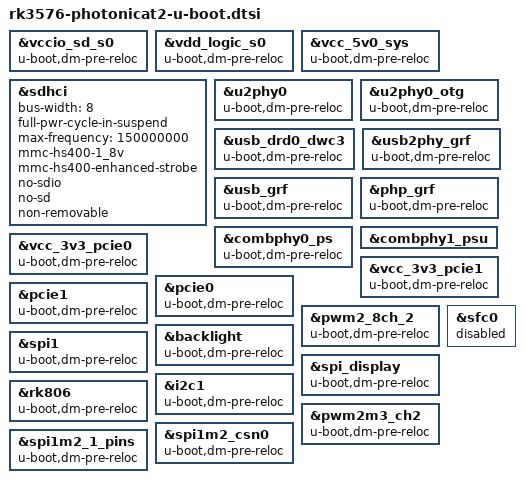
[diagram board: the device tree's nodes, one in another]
// SPDX-License-Identifier: (GPL-2.0+ OR MIT)
/*
 * Copyright (c) 2025 Rockchip Electronics Co., Ltd.
 * Copyright (c) 2025 Radxa Computer (Shenzhen) Co., Ltd.
*/

#include "rockchip/rk3576-u-boot.dtsi"

&vccio_sd_s0 {
	u-boot,dm-pre-reloc;
};

&vdd_logic_s0 {
	u-boot,dm-pre-reloc;
};

&vcc_5v0_sys {
	u-boot,dm-pre-reloc;
};

&sdhci {
	bus-width = <8>;
	full-pwr-cycle-in-suspend;
	max-frequency = <150000000>;
	mmc-hs400-1_8v;
	mmc-hs400-enhanced-strobe;

	/delete-property/ supports-cqe;

	no-sdio;
	no-sd;
	non-removable;
	status = "okay";
};

&u2phy0 {
	u-boot,dm-pre-reloc;
};

&u2phy0_otg {
	u-boot,dm-pre-reloc;
};

&usb_drd0_dwc3 {
	u-boot,dm-pre-reloc;
};

&usb2phy_grf {
	u-boot,dm-pre-reloc;
};

&usb_grf {
	u-boot,dm-pre-reloc;
};

&php_grf {
	u-boot,dm-pre-reloc;
};

&combphy0_ps {
	u-boot,dm-pre-reloc;
};

&combphy1_psu {
	status = "okay";
};

&vcc_3v3_pcie0 {
	u-boot,dm-pre-reloc;
};

&vcc_3v3_pcie1 {
	u-boot,dm-pre-reloc;
};

&pcie0 {
	u-boot,dm-pre-reloc;
};

&pcie1 {
	u-boot,dm-pre-reloc;
};

&pwm2_8ch_2 {
	u-boot,dm-pre-reloc;
};

&backlight {
	u-boot,dm-pre-reloc;
};

&spi1 {
	u-boot,dm-pre-reloc;
};

&spi_display {
	u-boot,dm-pre-reloc;
};

&i2c1 {
	u-boot,dm-pre-reloc;
};

&rk806 {
	u-boot,dm-pre-reloc;
};

&pwm2m3_ch2 {
	u-boot,dm-pre-reloc;
};

&spi1m2_csn0 {
	u-boot,dm-pre-reloc;
};

&spi1m2_1_pins {
	u-boot,dm-pre-reloc;
};

&sfc0 {
	status = "disabled";
};
